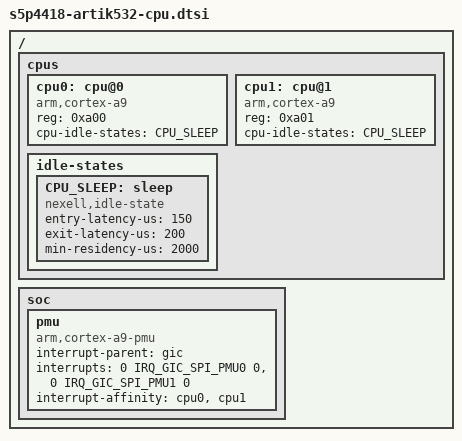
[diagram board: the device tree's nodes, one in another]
/*
 * Copyright (C) 2016  Nexell Co., Ltd.
 * Author: Youngbok, Park <ybpark@nexell.co.kr>
 *
 * This program is free software; you can redistribute it and/or
 * modify it under the terms of the GNU General Public License
 * as published by the Free Software Foundation; either version 2
 * of the License, or (at your option) any later version.
 *
 * This program is distributed in the hope that it will be useful,
 * but WITHOUT ANY WARRANTY; without even the implied warranty of
 * MERCHANTABILITY or FITNESS FOR A PARTICULAR PURPOSE.  See the
 * GNU General Public License for more details.
 *
 * You should have received a copy of the GNU General Public License
 * along with this program.  If not, see <http://www.gnu.org/licenses/>.
 */

/ {
	/delete-node/cpus;
	/delete-node/pmu;

	cpus {
		#address-cells = <0x1>;
		#size-cells = <0x0>;

		cpu0: cpu@0 {
			device_type = "cpu";
			compatible = "arm,cortex-a9";
			#cooling-cells = <2>;
			reg = <0xa00>;
			cpu-idle-states =<&CPU_SLEEP>;

		};

		cpu1: cpu@1 {
			device_type = "cpu";
			compatible = "arm,cortex-a9";
			reg = <0xa01>;
			cpu-idle-states =<&CPU_SLEEP>;
		};

		idle-states {
			CPU_SLEEP: sleep {
				compatible = "nexell,idle-state";
				entry-latency-us = <150>;
				exit-latency-us = <200>;
				min-residency-us = <2000>;
			};
		};
	};

	soc {
		pmu {
			compatible = "arm,cortex-a9-pmu";
			interrupt-parent = <&gic>;
			interrupts = <0 IRQ_GIC_SPI_PMU0 0>,
				     <0 IRQ_GIC_SPI_PMU1 0>;
			interrupt-affinity = <&cpu0>,
					     <&cpu1>;
		};
	};
};
